# ioam3358 register map
Registers are 32-bit, access not given, no defined reset value unless marked. A register's access mark holds for its fields unless they carry their own. Addresses are absolute; registers are grouped by the start of their names; [hi:lo] are bit positions; {n}, {i} and the like mark numbered series.

## CONF
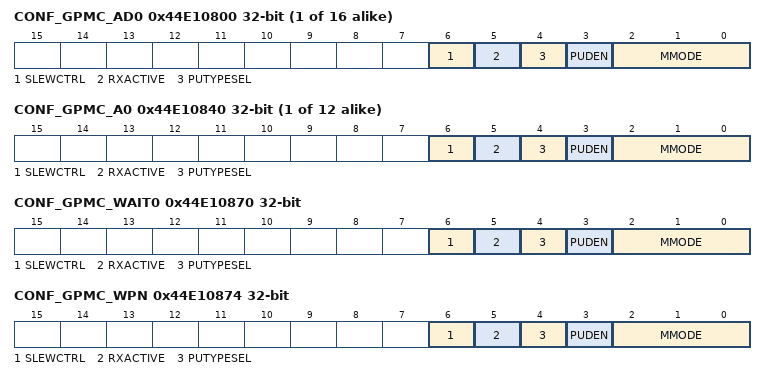
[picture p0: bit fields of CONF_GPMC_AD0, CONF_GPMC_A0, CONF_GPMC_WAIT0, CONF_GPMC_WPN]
{0x44E10800+4i} CONF_GPMC_AD{i} (i=0..15)
  [6] SLEWCTRL, [5] RXACTIVE, [4] PUTYPESEL, [3] PUDEN, [2:0] MMODE
{0x44E10840+4i} CONF_GPMC_A{i} (i=0..11)
  [6] SLEWCTRL, [5] RXACTIVE, [4] PUTYPESEL, [3] PUDEN, [2:0] MMODE
0x44E10870 CONF_GPMC_WAIT0
  [6] SLEWCTRL, [5] RXACTIVE, [4] PUTYPESEL, [3] PUDEN, [2:0] MMODE
0x44E10874 CONF_GPMC_WPN
  [6] SLEWCTRL, [5] RXACTIVE, [4] PUTYPESEL, [3] PUDEN, [2:0] MMODE
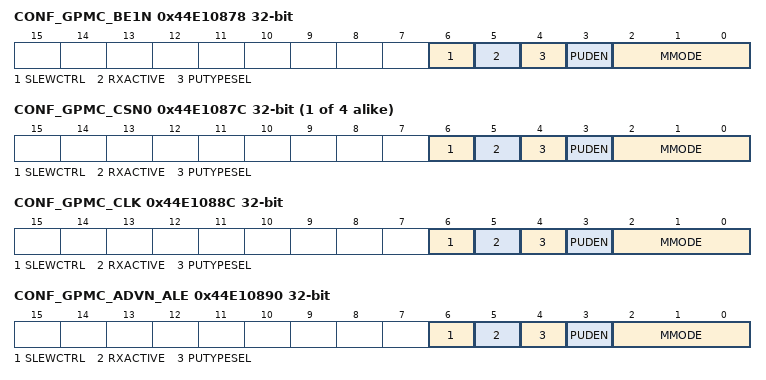
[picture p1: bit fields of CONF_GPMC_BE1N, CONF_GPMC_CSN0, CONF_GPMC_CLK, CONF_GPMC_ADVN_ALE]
0x44E10878 CONF_GPMC_BE1N
  [6] SLEWCTRL, [5] RXACTIVE, [4] PUTYPESEL, [3] PUDEN, [2:0] MMODE
{0x44E1087C+4i} CONF_GPMC_CSN{i} (i=0..3)
  [6] SLEWCTRL, [5] RXACTIVE, [4] PUTYPESEL, [3] PUDEN, [2:0] MMODE
0x44E1088C CONF_GPMC_CLK
  [6] SLEWCTRL, [5] RXACTIVE, [4] PUTYPESEL, [3] PUDEN, [2:0] MMODE
0x44E10890 CONF_GPMC_ADVN_ALE
  [6] SLEWCTRL, [5] RXACTIVE, [4] PUTYPESEL, [3] PUDEN, [2:0] MMODE
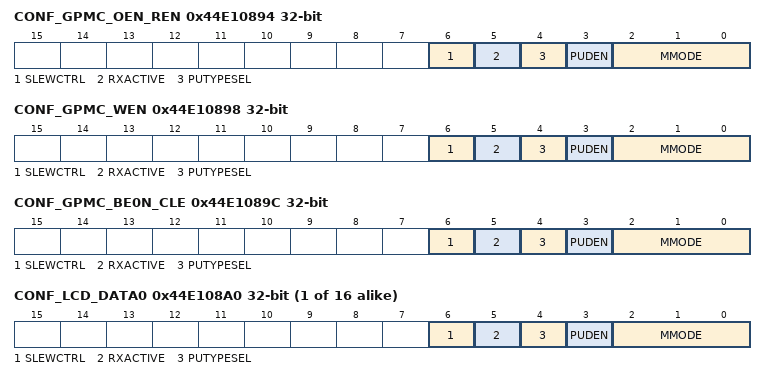
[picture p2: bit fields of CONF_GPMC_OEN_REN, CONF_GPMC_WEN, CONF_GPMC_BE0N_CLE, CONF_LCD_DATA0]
0x44E10894 CONF_GPMC_OEN_REN
  [6] SLEWCTRL, [5] RXACTIVE, [4] PUTYPESEL, [3] PUDEN, [2:0] MMODE
0x44E10898 CONF_GPMC_WEN
  [6] SLEWCTRL, [5] RXACTIVE, [4] PUTYPESEL, [3] PUDEN, [2:0] MMODE
0x44E1089C CONF_GPMC_BE0N_CLE
  [6] SLEWCTRL, [5] RXACTIVE, [4] PUTYPESEL, [3] PUDEN, [2:0] MMODE
{0x44E108A0+4i} CONF_LCD_DATA{i} (i=0..15)
  [6] SLEWCTRL, [5] RXACTIVE, [4] PUTYPESEL, [3] PUDEN, [2:0] MMODE
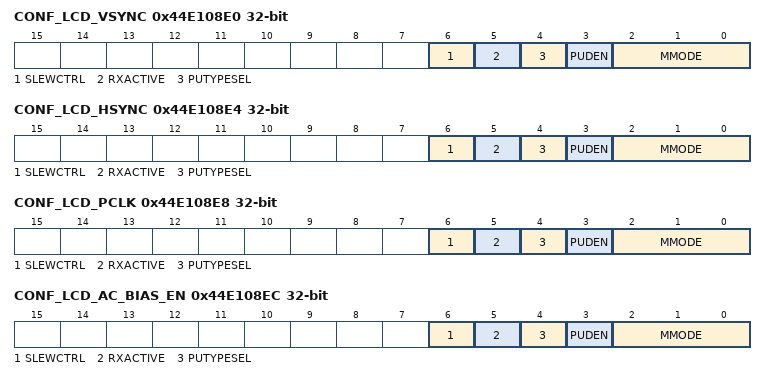
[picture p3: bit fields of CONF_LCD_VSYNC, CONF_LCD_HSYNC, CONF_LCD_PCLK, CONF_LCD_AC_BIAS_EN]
0x44E108E0 CONF_LCD_VSYNC
  [6] SLEWCTRL, [5] RXACTIVE, [4] PUTYPESEL, [3] PUDEN, [2:0] MMODE
0x44E108E4 CONF_LCD_HSYNC
  [6] SLEWCTRL, [5] RXACTIVE, [4] PUTYPESEL, [3] PUDEN, [2:0] MMODE
0x44E108E8 CONF_LCD_PCLK
  [6] SLEWCTRL, [5] RXACTIVE, [4] PUTYPESEL, [3] PUDEN, [2:0] MMODE
0x44E108EC CONF_LCD_AC_BIAS_EN
  [6] SLEWCTRL, [5] RXACTIVE, [4] PUTYPESEL, [3] PUDEN, [2:0] MMODE
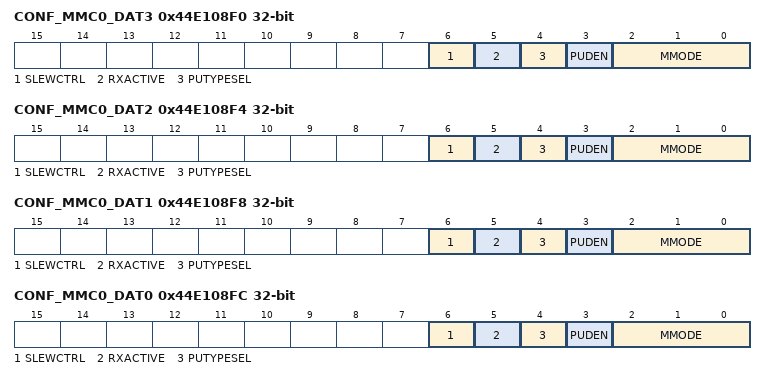
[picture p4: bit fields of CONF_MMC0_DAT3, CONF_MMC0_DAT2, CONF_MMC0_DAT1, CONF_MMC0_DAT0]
0x44E108F0 CONF_MMC0_DAT3
  [6] SLEWCTRL, [5] RXACTIVE, [4] PUTYPESEL, [3] PUDEN, [2:0] MMODE
0x44E108F4 CONF_MMC0_DAT2
  [6] SLEWCTRL, [5] RXACTIVE, [4] PUTYPESEL, [3] PUDEN, [2:0] MMODE
0x44E108F8 CONF_MMC0_DAT1
  [6] SLEWCTRL, [5] RXACTIVE, [4] PUTYPESEL, [3] PUDEN, [2:0] MMODE
0x44E108FC CONF_MMC0_DAT0
  [6] SLEWCTRL, [5] RXACTIVE, [4] PUTYPESEL, [3] PUDEN, [2:0] MMODE
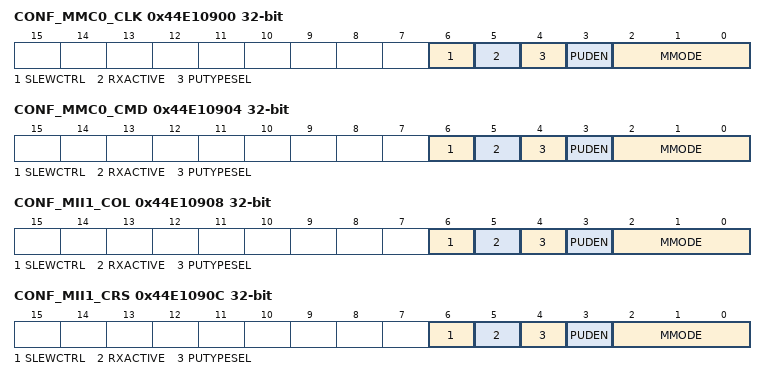
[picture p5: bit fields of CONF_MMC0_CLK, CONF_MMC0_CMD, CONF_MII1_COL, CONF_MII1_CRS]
0x44E10900 CONF_MMC0_CLK
  [6] SLEWCTRL, [5] RXACTIVE, [4] PUTYPESEL, [3] PUDEN, [2:0] MMODE
0x44E10904 CONF_MMC0_CMD
  [6] SLEWCTRL, [5] RXACTIVE, [4] PUTYPESEL, [3] PUDEN, [2:0] MMODE
0x44E10908 CONF_MII1_COL
  [6] SLEWCTRL, [5] RXACTIVE, [4] PUTYPESEL, [3] PUDEN, [2:0] MMODE
0x44E1090C CONF_MII1_CRS
  [6] SLEWCTRL, [5] RXACTIVE, [4] PUTYPESEL, [3] PUDEN, [2:0] MMODE
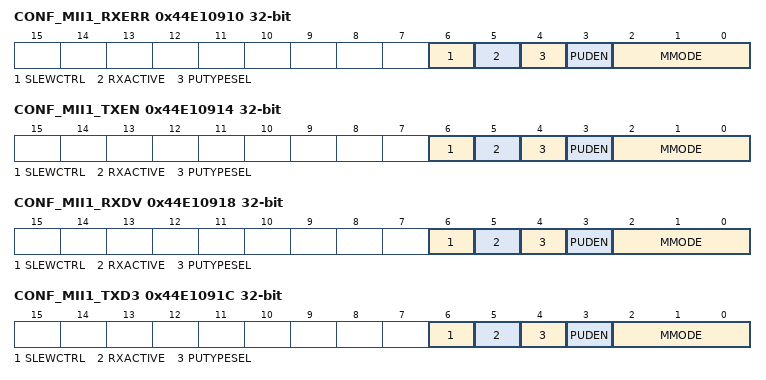
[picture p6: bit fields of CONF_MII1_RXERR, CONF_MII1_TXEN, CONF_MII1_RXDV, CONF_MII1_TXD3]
0x44E10910 CONF_MII1_RXERR
  [6] SLEWCTRL, [5] RXACTIVE, [4] PUTYPESEL, [3] PUDEN, [2:0] MMODE
0x44E10914 CONF_MII1_TXEN
  [6] SLEWCTRL, [5] RXACTIVE, [4] PUTYPESEL, [3] PUDEN, [2:0] MMODE
0x44E10918 CONF_MII1_RXDV
  [6] SLEWCTRL, [5] RXACTIVE, [4] PUTYPESEL, [3] PUDEN, [2:0] MMODE
0x44E1091C CONF_MII1_TXD3
  [6] SLEWCTRL, [5] RXACTIVE, [4] PUTYPESEL, [3] PUDEN, [2:0] MMODE
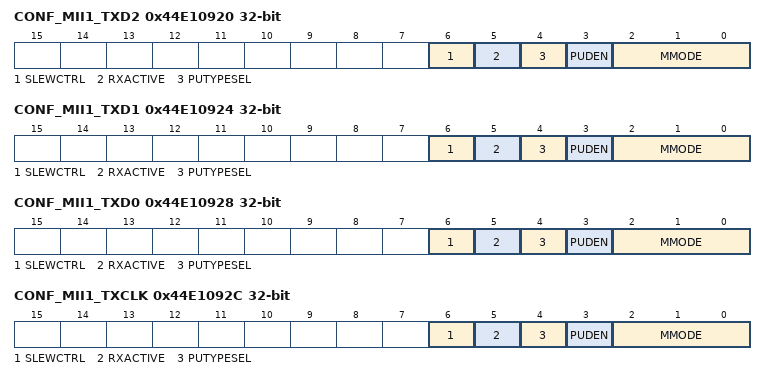
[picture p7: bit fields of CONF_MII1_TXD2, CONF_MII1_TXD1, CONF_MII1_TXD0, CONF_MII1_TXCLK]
0x44E10920 CONF_MII1_TXD2
  [6] SLEWCTRL, [5] RXACTIVE, [4] PUTYPESEL, [3] PUDEN, [2:0] MMODE
0x44E10924 CONF_MII1_TXD1
  [6] SLEWCTRL, [5] RXACTIVE, [4] PUTYPESEL, [3] PUDEN, [2:0] MMODE
0x44E10928 CONF_MII1_TXD0
  [6] SLEWCTRL, [5] RXACTIVE, [4] PUTYPESEL, [3] PUDEN, [2:0] MMODE
0x44E1092C CONF_MII1_TXCLK
  [6] SLEWCTRL, [5] RXACTIVE, [4] PUTYPESEL, [3] PUDEN, [2:0] MMODE
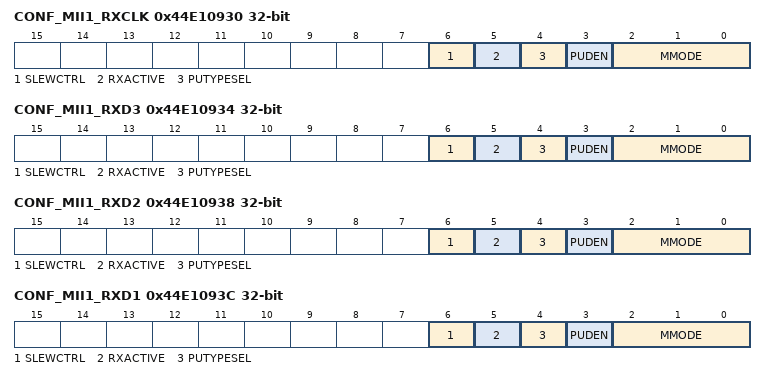
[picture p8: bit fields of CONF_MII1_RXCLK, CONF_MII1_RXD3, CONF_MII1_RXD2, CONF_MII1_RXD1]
0x44E10930 CONF_MII1_RXCLK
  [6] SLEWCTRL, [5] RXACTIVE, [4] PUTYPESEL, [3] PUDEN, [2:0] MMODE
0x44E10934 CONF_MII1_RXD3
  [6] SLEWCTRL, [5] RXACTIVE, [4] PUTYPESEL, [3] PUDEN, [2:0] MMODE
0x44E10938 CONF_MII1_RXD2
  [6] SLEWCTRL, [5] RXACTIVE, [4] PUTYPESEL, [3] PUDEN, [2:0] MMODE
0x44E1093C CONF_MII1_RXD1
  [6] SLEWCTRL, [5] RXACTIVE, [4] PUTYPESEL, [3] PUDEN, [2:0] MMODE
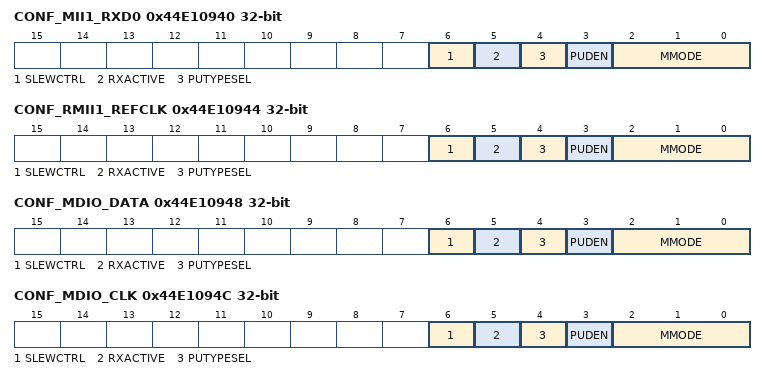
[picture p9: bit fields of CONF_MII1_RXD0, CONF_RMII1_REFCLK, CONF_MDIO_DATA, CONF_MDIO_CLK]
0x44E10940 CONF_MII1_RXD0
  [6] SLEWCTRL, [5] RXACTIVE, [4] PUTYPESEL, [3] PUDEN, [2:0] MMODE
0x44E10944 CONF_RMII1_REFCLK
  [6] SLEWCTRL, [5] RXACTIVE, [4] PUTYPESEL, [3] PUDEN, [2:0] MMODE
0x44E10948 CONF_MDIO_DATA
  [6] SLEWCTRL, [5] RXACTIVE, [4] PUTYPESEL, [3] PUDEN, [2:0] MMODE
0x44E1094C CONF_MDIO_CLK
  [6] SLEWCTRL, [5] RXACTIVE, [4] PUTYPESEL, [3] PUDEN, [2:0] MMODE
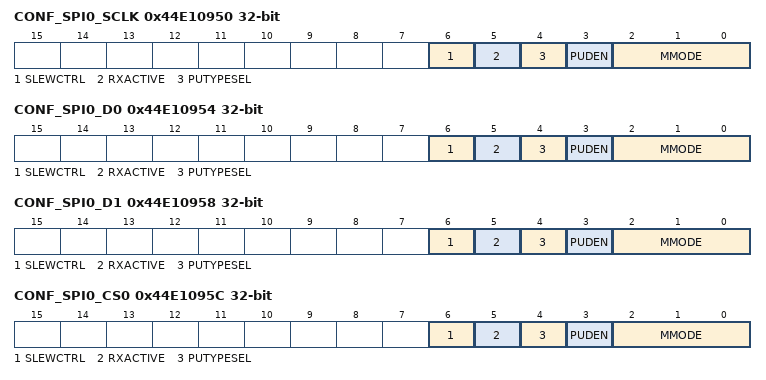
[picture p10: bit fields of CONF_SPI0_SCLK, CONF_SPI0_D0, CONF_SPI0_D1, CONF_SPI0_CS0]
0x44E10950 CONF_SPI0_SCLK
  [6] SLEWCTRL, [5] RXACTIVE, [4] PUTYPESEL, [3] PUDEN, [2:0] MMODE
0x44E10954 CONF_SPI0_D0
  [6] SLEWCTRL, [5] RXACTIVE, [4] PUTYPESEL, [3] PUDEN, [2:0] MMODE
0x44E10958 CONF_SPI0_D1
  [6] SLEWCTRL, [5] RXACTIVE, [4] PUTYPESEL, [3] PUDEN, [2:0] MMODE
0x44E1095C CONF_SPI0_CS0
  [6] SLEWCTRL, [5] RXACTIVE, [4] PUTYPESEL, [3] PUDEN, [2:0] MMODE
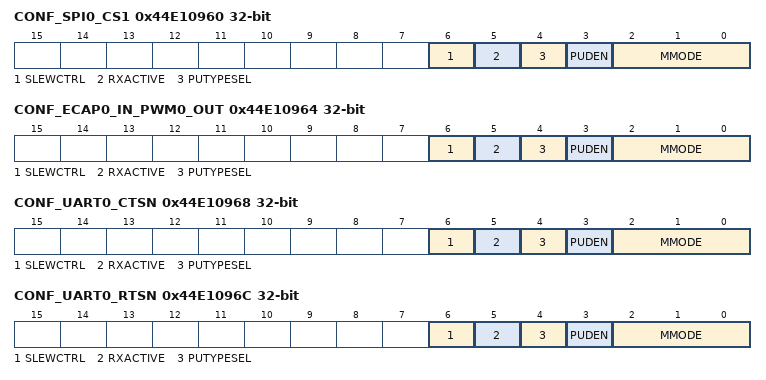
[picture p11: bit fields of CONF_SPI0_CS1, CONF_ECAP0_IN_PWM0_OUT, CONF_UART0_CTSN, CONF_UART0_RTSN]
0x44E10960 CONF_SPI0_CS1
  [6] SLEWCTRL, [5] RXACTIVE, [4] PUTYPESEL, [3] PUDEN, [2:0] MMODE
0x44E10964 CONF_ECAP0_IN_PWM0_OUT
  [6] SLEWCTRL, [5] RXACTIVE, [4] PUTYPESEL, [3] PUDEN, [2:0] MMODE
0x44E10968 CONF_UART0_CTSN
  [6] SLEWCTRL, [5] RXACTIVE, [4] PUTYPESEL, [3] PUDEN, [2:0] MMODE
0x44E1096C CONF_UART0_RTSN
  [6] SLEWCTRL, [5] RXACTIVE, [4] PUTYPESEL, [3] PUDEN, [2:0] MMODE
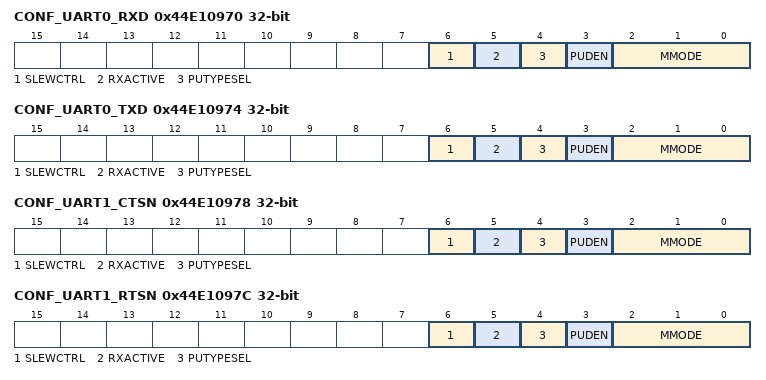
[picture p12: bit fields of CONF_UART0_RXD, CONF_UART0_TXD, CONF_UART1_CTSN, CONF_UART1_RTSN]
0x44E10970 CONF_UART0_RXD
  [6] SLEWCTRL, [5] RXACTIVE, [4] PUTYPESEL, [3] PUDEN, [2:0] MMODE
0x44E10974 CONF_UART0_TXD
  [6] SLEWCTRL, [5] RXACTIVE, [4] PUTYPESEL, [3] PUDEN, [2:0] MMODE
0x44E10978 CONF_UART1_CTSN
  [6] SLEWCTRL, [5] RXACTIVE, [4] PUTYPESEL, [3] PUDEN, [2:0] MMODE
0x44E1097C CONF_UART1_RTSN
  [6] SLEWCTRL, [5] RXACTIVE, [4] PUTYPESEL, [3] PUDEN, [2:0] MMODE
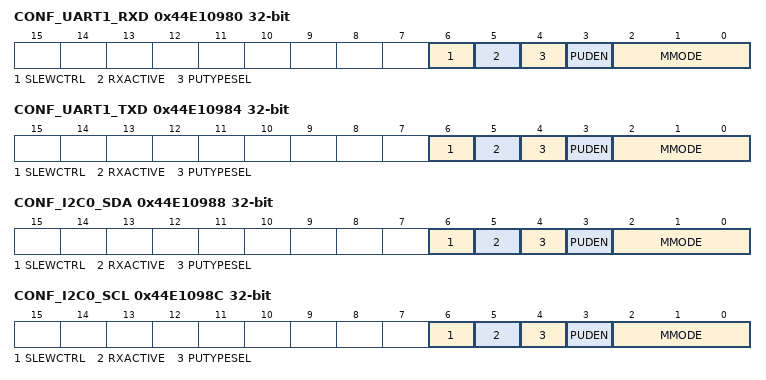
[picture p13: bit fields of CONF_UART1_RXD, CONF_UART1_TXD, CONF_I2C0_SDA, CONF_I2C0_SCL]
0x44E10980 CONF_UART1_RXD
  [6] SLEWCTRL, [5] RXACTIVE, [4] PUTYPESEL, [3] PUDEN, [2:0] MMODE
0x44E10984 CONF_UART1_TXD
  [6] SLEWCTRL, [5] RXACTIVE, [4] PUTYPESEL, [3] PUDEN, [2:0] MMODE
0x44E10988 CONF_I2C0_SDA
  [6] SLEWCTRL, [5] RXACTIVE, [4] PUTYPESEL, [3] PUDEN, [2:0] MMODE
0x44E1098C CONF_I2C0_SCL
  [6] SLEWCTRL, [5] RXACTIVE, [4] PUTYPESEL, [3] PUDEN, [2:0] MMODE
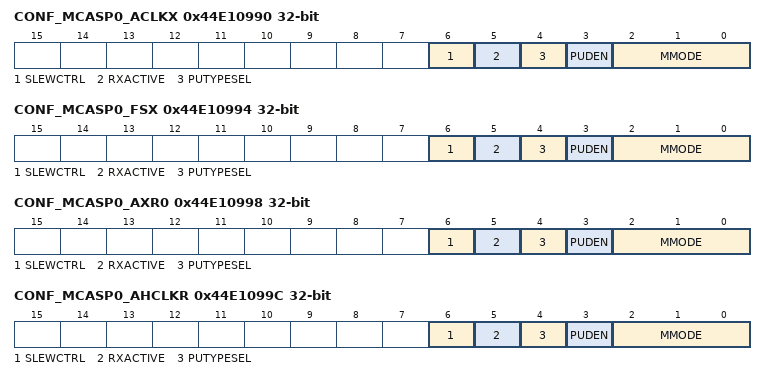
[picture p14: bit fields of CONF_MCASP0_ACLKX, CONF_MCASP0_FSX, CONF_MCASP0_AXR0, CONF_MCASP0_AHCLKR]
0x44E10990 CONF_MCASP0_ACLKX
  [6] SLEWCTRL, [5] RXACTIVE, [4] PUTYPESEL, [3] PUDEN, [2:0] MMODE
0x44E10994 CONF_MCASP0_FSX
  [6] SLEWCTRL, [5] RXACTIVE, [4] PUTYPESEL, [3] PUDEN, [2:0] MMODE
0x44E10998 CONF_MCASP0_AXR0
  [6] SLEWCTRL, [5] RXACTIVE, [4] PUTYPESEL, [3] PUDEN, [2:0] MMODE
0x44E1099C CONF_MCASP0_AHCLKR
  [6] SLEWCTRL, [5] RXACTIVE, [4] PUTYPESEL, [3] PUDEN, [2:0] MMODE
0x44E109A0 CONF_MCASP0_ACLKR
  [6] SLEWCTRL, [5] RXACTIVE, [4] PUTYPESEL, [3] PUDEN, [2:0] MMODE
0x44E109A4 CONF_MCASP0_FSR
  [6] SLEWCTRL, [5] RXACTIVE, [4] PUTYPESEL, [3] PUDEN, [2:0] MMODE
0x44E109A8 CONF_MCASP0_AXR1
  [6] SLEWCTRL, [5] RXACTIVE, [4] PUTYPESEL, [3] PUDEN, [2:0] MMODE
0x44E109AC CONF_MCASP0_AHCLKX
  [6] SLEWCTRL, [5] RXACTIVE, [4] PUTYPESEL, [3] PUDEN, [2:0] MMODE
0x44E109B0 CONF_XDMA_EVENT_INTR0
  [6] SLEWCTRL, [5] RXACTIVE, [4] PUTYPESEL, [3] PUDEN, [2:0] MMODE
0x44E109B4 CONF_XDMA_EVENT_INTR1
  [6] SLEWCTRL, [5] RXACTIVE, [4] PUTYPESEL, [3] PUDEN, [2:0] MMODE
0x44E109B8 CONF_NRESETIN_OUT
  [6] SLEWCTRL, [5] RXACTIVE, [4] PUTYPESEL, [3] PUDEN, [2:0] MMODE
0x44E109BC CONF_PORZ
  [6] SLEWCTRL, [5] RXACTIVE, [4] PUTYPESEL, [3] PUDEN, [2:0] MMODE
0x44E109C0 CONF_NNMI
  [6] SLEWCTRL, [5] RXACTIVE, [4] PUTYPESEL, [3] PUDEN, [2:0] MMODE
0x44E109C4 CONF_OSC0_IN
  [6] SLEWCTRL, [5] RXACTIVE, [4] PUTYPESEL, [3] PUDEN, [2:0] MMODE
0x44E109C8 CONF_OSC0_OUT
  [6] SLEWCTRL, [5] RXACTIVE, [4] PUTYPESEL, [3] PUDEN, [2:0] MMODE
0x44E109CC CONF_OSC0_VSS
  [6] SLEWCTRL, [5] RXACTIVE, [4] PUTYPESEL, [3] PUDEN, [2:0] MMODE
0x44E109D0 CONF_TMS
  [6] SLEWCTRL, [5] RXACTIVE, [4] PUTYPESEL, [3] PUDEN, [2:0] MMODE
0x44E109D4 CONF_TDI
  [6] SLEWCTRL, [5] RXACTIVE, [4] PUTYPESEL, [3] PUDEN, [2:0] MMODE
0x44E109D8 CONF_TDO
  [6] SLEWCTRL, [5] RXACTIVE, [4] PUTYPESEL, [3] PUDEN, [2:0] MMODE
0x44E109DC CONF_TCK
  [6] SLEWCTRL, [5] RXACTIVE, [4] PUTYPESEL, [3] PUDEN, [2:0] MMODE
0x44E109E0 CONF_NTRST
  [6] SLEWCTRL, [5] RXACTIVE, [4] PUTYPESEL, [3] PUDEN, [2:0] MMODE
0x44E109E4 CONF_EMU0
  [6] SLEWCTRL, [5] RXACTIVE, [4] PUTYPESEL, [3] PUDEN, [2:0] MMODE
0x44E109E8 CONF_EMU1
  [6] SLEWCTRL, [5] RXACTIVE, [4] PUTYPESEL, [3] PUDEN, [2:0] MMODE
0x44E109EC CONF_OSC1_IN
  [6] SLEWCTRL, [5] RXACTIVE, [4] PUTYPESEL, [3] PUDEN, [2:0] MMODE
0x44E109F0 CONF_OSC1_OUT
  [6] SLEWCTRL, [5] RXACTIVE, [4] PUTYPESEL, [3] PUDEN, [2:0] MMODE
0x44E109F4 CONF_OSC1_VSS
  [6] SLEWCTRL, [5] RXACTIVE, [4] PUTYPESEL, [3] PUDEN, [2:0] MMODE
0x44E109F8 CONF_RTC_PORZ
  [6] SLEWCTRL, [5] RXACTIVE, [4] PUTYPESEL, [3] PUDEN, [2:0] MMODE
0x44E109FC CONF_PMIC_POWER_EN
  [6] SLEWCTRL, [5] RXACTIVE, [4] PUTYPESEL, [3] PUDEN, [2:0] MMODE
0x44E10A00 CONF_EXT_WAKEUP
  [6] SLEWCTRL, [5] RXACTIVE, [4] PUTYPESEL, [3] PUDEN, [2:0] MMODE
0x44E10A04 CONF_ENZ_KALDO_1P8V
  [6] SLEWCTRL, [5] RXACTIVE, [4] PUTYPESEL, [3] PUDEN, [2:0] MMODE
0x44E10A08 CONF_USB0_DM
  [6] SLEWCTRL, [5] RXACTIVE, [4] PUTYPESEL, [3] PUDEN, [2:0] MMODE
0x44E10A0C CONF_USB0_DP
  [6] SLEWCTRL, [5] RXACTIVE, [4] PUTYPESEL, [3] PUDEN, [2:0] MMODE
0x44E10A10 CONF_USB0_CE
  [6] SLEWCTRL, [5] RXACTIVE, [4] PUTYPESEL, [3] PUDEN, [2:0] MMODE
0x44E10A14 CONF_USB0_ID
  [6] SLEWCTRL, [5] RXACTIVE, [4] PUTYPESEL, [3] PUDEN, [2:0] MMODE
0x44E10A18 CONF_USB0_VBUS
  [6] SLEWCTRL, [5] RXACTIVE, [4] PUTYPESEL, [3] PUDEN, [2:0] MMODE
0x44E10A1C CONF_USB0_DRVVBUS
  [6] SLEWCTRL, [5] RXACTIVE, [4] PUTYPESEL, [3] PUDEN, [2:0] MMODE
0x44E10A20 CONF_USB1_DM
  [6] SLEWCTRL, [5] RXACTIVE, [4] PUTYPESEL, [3] PUDEN, [2:0] MMODE
0x44E10A24 CONF_USB1_DP
  [6] SLEWCTRL, [5] RXACTIVE, [4] PUTYPESEL, [3] PUDEN, [2:0] MMODE
0x44E10A28 CONF_USB1_CE
  [6] SLEWCTRL, [5] RXACTIVE, [4] PUTYPESEL, [3] PUDEN, [2:0] MMODE
0x44E10A2C CONF_USB1_ID
  [6] SLEWCTRL, [5] RXACTIVE, [4] PUTYPESEL, [3] PUDEN, [2:0] MMODE
0x44E10A30 CONF_USB1_VBUS
  [6] SLEWCTRL, [5] RXACTIVE, [4] PUTYPESEL, [3] PUDEN, [2:0] MMODE
0x44E10A34 CONF_USB1_DRVVBUS
  [6] SLEWCTRL, [5] RXACTIVE, [4] PUTYPESEL, [3] PUDEN, [2:0] MMODE
0x44E10A38 CONF_DDR_RESETN
  [6] SLEWCTRL, [5] RXACTIVE, [4] PUTYPESEL, [3] PUDEN, [2:0] MMODE
0x44E10A3C CONF_DDR_CSN0
  [6] SLEWCTRL, [5] RXACTIVE, [4] PUTYPESEL, [3] PUDEN, [2:0] MMODE
0x44E10A40 CONF_DDR_CKE
  [6] SLEWCTRL, [5] RXACTIVE, [4] PUTYPESEL, [3] PUDEN, [2:0] MMODE
0x44E10A48 CONF_DDR_NCK
  [6] SLEWCTRL, [5] RXACTIVE, [4] PUTYPESEL, [3] PUDEN, [2:0] MMODE
0x44E10A4C CONF_DDR_CASN
  [6] SLEWCTRL, [5] RXACTIVE, [4] PUTYPESEL, [3] PUDEN, [2:0] MMODE
0x44E10A50 CONF_DDR_RASN
  [6] SLEWCTRL, [5] RXACTIVE, [4] PUTYPESEL, [3] PUDEN, [2:0] MMODE
0x44E10A54 CONF_DDR_WEN
  [6] SLEWCTRL, [5] RXACTIVE, [4] PUTYPESEL, [3] PUDEN, [2:0] MMODE
{0x44E10A58+4i} CONF_DDR_BA{i} (i=0..2)
  [6] SLEWCTRL, [5] RXACTIVE, [4] PUTYPESEL, [3] PUDEN, [2:0] MMODE
{0x44E10A64+4i} CONF_DDR_A{i} (i=0..15)
  [6] SLEWCTRL, [5] RXACTIVE, [4] PUTYPESEL, [3] PUDEN, [2:0] MMODE
0x44E10AA4 CONF_DDR_ODT
  [6] SLEWCTRL, [5] RXACTIVE, [4] PUTYPESEL, [3] PUDEN, [2:0] MMODE
{0x44E10AA8+4i} CONF_DDR_D{i} (i=0..15)
  [6] SLEWCTRL, [5] RXACTIVE, [4] PUTYPESEL, [3] PUDEN, [2:0] MMODE
0x44E10AE8 CONF_DDR_DQM0
  [6] SLEWCTRL, [5] RXACTIVE, [4] PUTYPESEL, [3] PUDEN, [2:0] MMODE
0x44E10AEC CONF_DDR_DQM1
  [6] SLEWCTRL, [5] RXACTIVE, [4] PUTYPESEL, [3] PUDEN, [2:0] MMODE
0x44E10AF0 CONF_DDR_DQS0
  [6] SLEWCTRL, [5] RXACTIVE, [4] PUTYPESEL, [3] PUDEN, [2:0] MMODE
0x44E10AF4 CONF_DDR_DQSN0
  [6] SLEWCTRL, [5] RXACTIVE, [4] PUTYPESEL, [3] PUDEN, [2:0] MMODE
0x44E10AF8 CONF_DDR_DQS1
  [6] SLEWCTRL, [5] RXACTIVE, [4] PUTYPESEL, [3] PUDEN, [2:0] MMODE
0x44E10AFC CONF_DDR_DQSN1
  [6] SLEWCTRL, [5] RXACTIVE, [4] PUTYPESEL, [3] PUDEN, [2:0] MMODE
0x44E10B00 CONF_DDR_VREF
  [6] SLEWCTRL, [5] RXACTIVE, [4] PUTYPESEL, [3] PUDEN, [2:0] MMODE
0x44E10B04 CONF_DDR_VTP
  [6] SLEWCTRL, [5] RXACTIVE, [4] PUTYPESEL, [3] PUDEN, [2:0] MMODE
0x44E10B08 CONF_DDR_STRBEN0
  [6] SLEWCTRL, [5] RXACTIVE, [4] PUTYPESEL, [3] PUDEN, [2:0] MMODE
0x44E10B0C CONF_DDR_STRBEN1
  [6] SLEWCTRL, [5] RXACTIVE, [4] PUTYPESEL, [3] PUDEN, [2:0] MMODE
0x44E10B10 CONF_AIN7
  [6] SLEWCTRL, [5] RXACTIVE, [4] PUTYPESEL, [3] PUDEN, [2:0] MMODE
0x44E10B14 CONF_AIN6
  [6] SLEWCTRL, [5] RXACTIVE, [4] PUTYPESEL, [3] PUDEN, [2:0] MMODE
0x44E10B18 CONF_AIN5
  [6] SLEWCTRL, [5] RXACTIVE, [4] PUTYPESEL, [3] PUDEN, [2:0] MMODE
0x44E10B1C CONF_AIN4
  [6] SLEWCTRL, [5] RXACTIVE, [4] PUTYPESEL, [3] PUDEN, [2:0] MMODE
0x44E10B20 CONF_AIN3
  [6] SLEWCTRL, [5] RXACTIVE, [4] PUTYPESEL, [3] PUDEN, [2:0] MMODE
0x44E10B24 CONF_AIN2
  [6] SLEWCTRL, [5] RXACTIVE, [4] PUTYPESEL, [3] PUDEN, [2:0] MMODE
0x44E10B28 CONF_AIN1
  [6] SLEWCTRL, [5] RXACTIVE, [4] PUTYPESEL, [3] PUDEN, [2:0] MMODE
0x44E10B2C CONF_AIN0
  [6] SLEWCTRL, [5] RXACTIVE, [4] PUTYPESEL, [3] PUDEN, [2:0] MMODE
0x44E10B30 CONF_VREFP
  [6] SLEWCTRL, [5] RXACTIVE, [4] PUTYPESEL, [3] PUDEN, [2:0] MMODE
0x44E10B34 CONF_VREFN
  [6] SLEWCTRL, [5] RXACTIVE, [4] PUTYPESEL, [3] PUDEN, [2:0] MMODE
0x44E10B38 CONF_AVDD
  [6] SLEWCTRL, [5] RXACTIVE, [4] PUTYPESEL, [3] PUDEN, [2:0] MMODE
0x44E10B3C CONF_AVSS
  [6] SLEWCTRL, [5] RXACTIVE, [4] PUTYPESEL, [3] PUDEN, [2:0] MMODE
0x44E10B40 CONF_IFORCE
  [6] SLEWCTRL, [5] RXACTIVE, [4] PUTYPESEL, [3] PUDEN, [2:0] MMODE
0x44E10B44 CONF_VSENSE
  [6] SLEWCTRL, [5] RXACTIVE, [4] PUTYPESEL, [3] PUDEN, [2:0] MMODE
0x44E10B48 CONF_TESTOUT
  [6] SLEWCTRL, [5] RXACTIVE, [4] PUTYPESEL, [3] PUDEN, [2:0] MMODE
